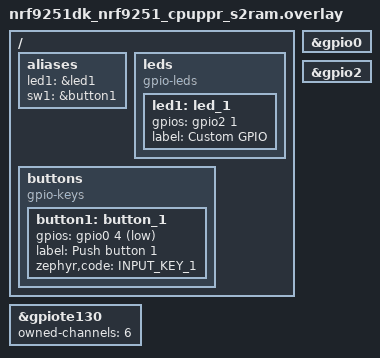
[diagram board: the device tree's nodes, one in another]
/*
 * Copyright (c) 2026 Nordic Semiconductor ASA
 *
 * SPDX-License-Identifier: LicenseRef-Nordic-5-Clause
 */

/ {
	aliases {
		led1 = &led1;
		sw1 = &button1;
	};

	leds {
		compatible = "gpio-leds";

		/* Move to other GPIO. */
		led1: led_1 {
			gpios = <&gpio2 1 GPIO_ACTIVE_HIGH>;
			label = "Custom GPIO";
		};
	};

	buttons {
		compatible = "gpio-keys";

		button1: button_1 {
			gpios = <&gpio0 4 (GPIO_PULL_UP | GPIO_ACTIVE_LOW)>;
			label = "Push button 1";
			zephyr,code = <INPUT_KEY_1>;
		};
	};
};

&gpio0 {
	status = "okay";
};

&gpio2 {
	status = "okay";
};

&gpiote130 {
	status = "okay";
	owned-channels = <6>;
};
